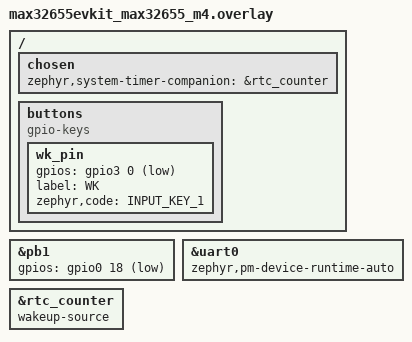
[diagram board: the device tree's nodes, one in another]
/*
 * SPDX-License-Identifier: Apache-2.0
 *
 * Copyright (c) 2024-2026 Analog Devices, Inc.
 */

/ {
	chosen {
		zephyr,system-timer-companion = &rtc_counter;
	};

	buttons {
		compatible = "gpio-keys";

		wk_pin: wk_pin {
			gpios = <&gpio3 0 (GPIO_ACTIVE_LOW | GPIO_PULL_UP)>;
			label = "WK";
			zephyr,code = <INPUT_KEY_1>;
		};
	};
};

&pb1 {
	gpios = <&gpio0 18 (GPIO_PULL_UP | GPIO_ACTIVE_LOW)>;
};

&uart0 {
	zephyr,pm-device-runtime-auto;
};

&rtc_counter {
	status = "okay";
	wakeup-source;
};
